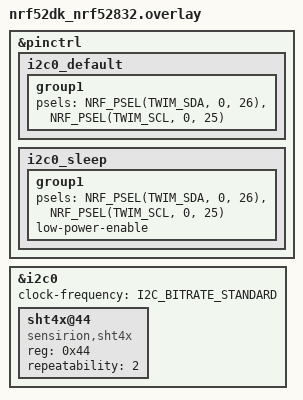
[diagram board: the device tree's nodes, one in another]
&pinctrl {
	i2c0_default: i2c0_default {
		group1 {
			psels = <NRF_PSEL(TWIM_SDA, 0, 26)>,  
				<NRF_PSEL(TWIM_SCL, 0, 25)>;      
		};
	};

	i2c0_sleep: i2c0_sleep {
		group1 {
			psels = <NRF_PSEL(TWIM_SDA, 0, 26)>,   
				<NRF_PSEL(TWIM_SCL, 0, 25)>;        
			low-power-enable;
		};
	};
};


 &i2c0 {
	status = "okay";
	clock-frequency = <I2C_BITRATE_STANDARD>;
	sht4x@44 {
		status = "okay";
		compatible = "sensirion,sht4x";
		reg = <0x44>;
		repeatability = <2>;
	};
};

